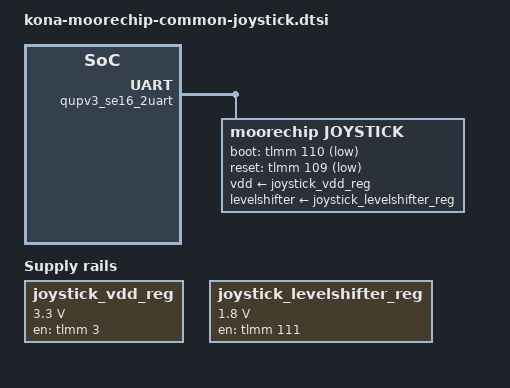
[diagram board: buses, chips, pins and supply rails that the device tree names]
&soc {
	joystick_vdd_reg: joystick_vdd_reg {
		compatible = "regulator-fixed";
		regulator-name = "joystick_vdd_reg";
		regulator-min-microvolt = <3300000>;
		regulator-max-microvolt = <3300000>;
		enable-active-high;
		gpio = <&tlmm 3 GPIO_ACTIVE_HIGH>;
	};

	// AW3911
	joystick_levelshifter_reg: joystick_levelshifter_reg {
		compatible = "regulator-fixed";
		regulator-name = "joystick_levelshifter_reg";
		regulator-min-microvolt = <1800000>;
		regulator-max-microvolt = <1800000>;
		enable-active-high;
		gpio = <&tlmm 111 GPIO_ACTIVE_HIGH>;
	};
};

&qupv3_se16_2uart {
	status = "okay";

	joystick: joystick {
		status = "okay";
		compatible = "moorechip,joystick";
		vdd-supply = <&joystick_vdd_reg>;
		levelshifter-supply = <&joystick_levelshifter_reg>;

		moorechip,boot-gpio = <&tlmm 110 GPIO_ACTIVE_LOW>;
		moorechip,reset-gpio = <&tlmm 109 GPIO_ACTIVE_LOW>;
	};
};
